# MCU_FSS0_HYPERBUS1P0_0_HPB_SS_CFG register map
Vendor: Texas Instruments
Peripheral module from a debugger description file (folder J721S2).
Registers are 32-bit, read-only, reset 0x0 unless marked. A register's access mark holds for its fields unless they carry their own. Offsets are as the file gives them; lines under a group give offsets from that group; [hi:lo] are bit positions; {n}, {i} and the like mark numbered series; 'fields as' and 'values as' point back to an identical list; <NAME> marks a mode.

## MCU_FSS0_HYPERBUS1P0_0_HPB_SS_CFG
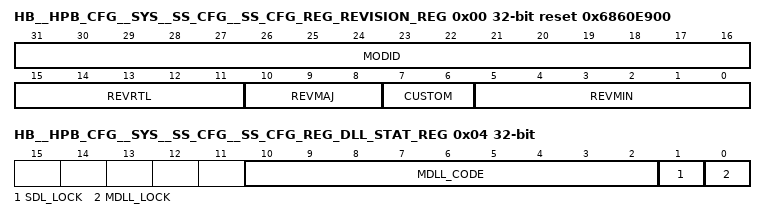
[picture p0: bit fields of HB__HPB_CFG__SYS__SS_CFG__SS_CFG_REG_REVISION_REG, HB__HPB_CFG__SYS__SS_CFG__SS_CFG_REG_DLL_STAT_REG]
0x00 HB__HPB_CFG__SYS__SS_CFG__SS_CFG_REG_REVISION_REG reset 0x6860E900 — The Revision Register contains the major and minor revisions for the module
  [31:16] MODID — Module ID field
  [15:11] REVRTL — RTL revision. Will vary depending on release
  [10:8] REVMAJ — Major revision
  [7:6] CUSTOM
  [5:0] REVMIN — Minor revision
0x04 HB__HPB_CFG__SYS__SS_CFG__SS_CFG_REG_DLL_STAT_REG — DLL status register
  [10:2] MDLL_CODE — MDLL code. The slave delay line length that is currently enabled is determined by the MDLL code value
  [1] SDL_LOCK — SDL lock. When this bit is set, it indicates that the slave delay line in the MDLL is locked.
  [0] MDLL_LOCK — MDLL lock. When this bit is set, it indicates that the master delay line in the MDLL is locked.
0x08 HB__HPB_CFG__SYS__SS_CFG__SS_CFG_REG_RAM_STAT_REG — RAM status register
  [0] INIT_DONE — FIFO RAM initialization done. When this bit is set, t indicates that all the FIFO RAM auto initialization is complete. Software should check that this bit is set before initiating transactions to the external memory
